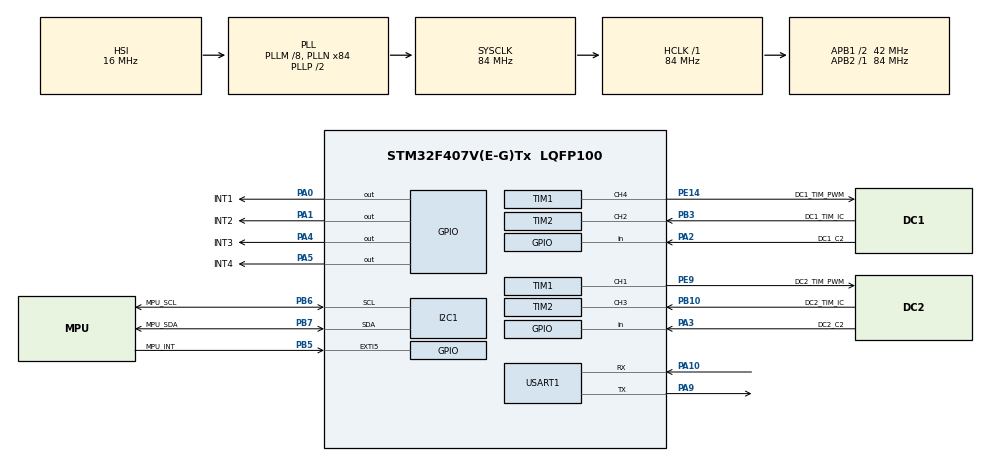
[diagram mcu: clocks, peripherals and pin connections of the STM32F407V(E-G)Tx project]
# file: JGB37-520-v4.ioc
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I2C1.I2C_Mode=I2C_Fast
Mcu.Family=STM32F4
Mcu.Name=STM32F407V(E-G)Tx
Mcu.Package=LQFP100
NVIC.EXTI9_5_IRQn=true\:0\:0\:false\:false\:true\:true\:true
NVIC.PriorityGroup=NVIC_PRIORITYGROUP_4
NVIC.TIM2_IRQn=true\:0\:0\:false\:false\:true\:true\:true
NVIC.TIM3_IRQn=true\:0\:0\:false\:false\:true\:true\:true
NVIC.TIM4_IRQn=true\:0\:0\:false\:false\:true\:true\:true
NVIC.USART1_IRQn=true\:0\:0\:false\:false\:true\:true\:true
PA0-WKUP.GPIO_Label=INT1
PA0-WKUP.GPIO_Speed=GPIO_SPEED_FREQ_HIGH
PA0-WKUP.PinState=GPIO_PIN_SET
PA0-WKUP.Signal=GPIO_Output
PA1.GPIO_Label=INT2
PA1.GPIO_Speed=GPIO_SPEED_FREQ_HIGH
PA1.PinState=GPIO_PIN_SET
PA1.Signal=GPIO_Output
PA10.Mode=Asynchronous
PA10.Signal=USART1_RX
PA13.Mode=Serial_Wire
PA13.Signal=SYS_JTMS-SWDIO
PA14.Mode=Serial_Wire
PA14.Signal=SYS_JTCK-SWCLK
PA2.GPIO_Label=DC1_C2
PA2.Signal=GPIO_Input
PA3.GPIO_Label=DC2_C2
PA3.Signal=GPIO_Input
PA4.GPIO_Label=INT3
PA4.GPIO_Speed=GPIO_SPEED_FREQ_HIGH
PA4.Signal=GPIO_Output
PA5.GPIO_Label=INT4
PA5.GPIO_Speed=GPIO_SPEED_FREQ_HIGH
PA5.Signal=GPIO_Output
PA9.Mode=Asynchronous
PA9.Signal=USART1_TX
PB10.GPIO_Label=DC2_TIM_IC
PB10.GPIO_Speed=GPIO_SPEED_FREQ_HIGH
PB10.Signal=S_TIM2_CH3
PB3.GPIO_Label=DC1_TIM_IC
PB3.GPIO_Speed=GPIO_SPEED_FREQ_HIGH
PB3.Signal=S_TIM2_CH2
PB5.GPIO_Label=MPU_INT
PB5.Signal=GPXTI5
PB6.GPIO_Label=MPU_SCL
PB6.GPIO_Speed=GPIO_SPEED_FREQ_HIGH
PB6.Mode=I2C
PB6.Signal=I2C1_SCL
PB7.GPIO_Label=MPU_SDA
PB7.GPIO_Speed=GPIO_SPEED_FREQ_HIGH
PB7.Mode=I2C
PB7.Signal=I2C1_SDA
PE14.GPIO_Label=DC1_TIM_PWM
PE14.GPIO_Speed=GPIO_SPEED_FREQ_HIGH
PE14.Signal=S_TIM1_CH4
PE9.GPIO_Label=DC2_TIM_PWM
PE9.GPIO_Speed=GPIO_SPEED_FREQ_HIGH
PE9.Signal=S_TIM1_CH1
ProjectManager.HeapSize=0x200
ProjectManager.StackSize=0x400
ProjectManager.TargetToolchain=STM32CubeIDE
RCC.48MHZClocksFreq_Value=42000000
RCC.AHBFreq_Value=84000000
RCC.APB1CLKDivider=RCC_HCLK_DIV2
RCC.APB1Freq_Value=42000000
RCC.APB1TimFreq_Value=84000000
RCC.APB2Freq_Value=84000000
RCC.APB2TimFreq_Value=84000000
RCC.CortexFreq_Value=84000000
RCC.HCLKFreq_Value=84000000
RCC.HSE_VALUE=25000000
RCC.HSI_VALUE=16000000
RCC.LSE_VALUE=32768
RCC.PLLM=8
RCC.PLLN=84
RCC.SYSCLKFreq_VALUE=84000000
RCC.SYSCLKSource=RCC_SYSCLKSOURCE_PLLCLK
RCC.VCOOutputFreq_Value=168000000
SH.S_TIM1_CH1.0=TIM1_CH1,PWM Generation1 CH1
SH.S_TIM1_CH4.0=TIM1_CH4,PWM Generation4 CH4
SH.S_TIM2_CH2.0=TIM2_CH2,Input_Capture2_from_TI2
SH.S_TIM2_CH3.0=TIM2_CH3,Input_Capture3_from_TI3
TIM1.Channel-PWM\ Generation1\ CH1=TIM_CHANNEL_1
TIM1.Channel-PWM\ Generation4\ CH4=TIM_CHANNEL_4
TIM2.Channel-Input_Capture2_from_TI2=TIM_CHANNEL_2
TIM2.Channel-Input_Capture3_from_TI3=TIM_CHANNEL_3
TIM3.Period=9999
TIM3.Prescaler=419
TIM4.Period=19999
TIM4.Prescaler=8399
USART1.VirtualMode=VM_ASYNC
VP_TIM1_VS_ClockSourceINT.Mode=Internal
VP_TIM2_VS_ClockSourceINT.Mode=Internal
VP_TIM3_VS_ClockSourceINT.Mode=Internal
VP_TIM4_VS_ClockSourceINT.Mode=Internal
board=custom

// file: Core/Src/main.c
/* USER CODE BEGIN Header */
/**
  ******************************************************************************
  * @file           : main.c
  * @brief          : Main program body
  ******************************************************************************
  * @attention
  *
  * <h2><center>&copy; Copyright (c) 2022 STMicroelectronics.
  * All rights reserved.</center></h2>
  *
  * This software component is licensed by ST under BSD 3-Clause license,
  * the "License"; You may not use this file except in compliance with the
  * License. You may obtain a copy of the License at:
  *                        opensource.org/licenses/BSD-3-Clause
  *
  ******************************************************************************
  */
/* USER CODE END Header */
#include "main.h"

I2C_HandleTypeDef hi2c1;

TIM_HandleTypeDef htim1;
TIM_HandleTypeDef htim2;
TIM_HandleTypeDef htim3;
TIM_HandleTypeDef htim4;

UART_HandleTypeDef huart1;

void SystemClock_Config(void);
static void MX_GPIO_Init(void);
static void MX_TIM1_Init(void);
static void MX_TIM2_Init(void);
static void MX_TIM3_Init(void);
static void MX_TIM4_Init(void);
static void MX_I2C1_Init(void);
static void MX_USART1_UART_Init(void);

int main(void)
{

  /* MCU Configuration--------------------------------------------------------*/

  /* Reset of all peripherals, Initializes the Flash interface and the Systick. */
  HAL_Init();

  /* Configure the system clock */
  SystemClock_Config();

  /* Initialize all configured peripherals */
  MX_GPIO_Init();
  MX_TIM1_Init();
  MX_TIM2_Init();
  MX_TIM3_Init();
  MX_TIM4_Init();
  MX_I2C1_Init();
  MX_USART1_UART_Init();
  /* USER CODE BEGIN 2 */
  HAL_GPIO_WritePin(GPIOA, GPIO_PIN_0, RESET);
  HAL_GPIO_WritePin(GPIOA, GPIO_PIN_1, SET);
//  HAL_GPIO_WritePin(GPIOA, GPIO_PIN_2, SET);

  HAL_TIM_PWM_Start(&htim1, TIM_CHANNEL_4);

  __HAL_TIM_SET_COMPARE(&htim1, TIM_CHANNEL_4, 8000);
  /* USER CODE END 2 */

  /* Infinite loop */
  while (1)
  {

  }
}

void SystemClock_Config(void)
{
  RCC_OscInitTypeDef RCC_OscInitStruct = {0};
  RCC_ClkInitTypeDef RCC_ClkInitStruct = {0};

  /** Configure the main internal regulator output voltage
  */
  __HAL_RCC_PWR_CLK_ENABLE();
  __HAL_PWR_VOLTAGESCALING_CONFIG(PWR_REGULATOR_VOLTAGE_SCALE1);
  /** Initializes the RCC Oscillators according to the specified parameters
  * in the RCC_OscInitTypeDef structure.
  */
  RCC_OscInitStruct.OscillatorType = RCC_OSCILLATORTYPE_HSI;
  RCC_OscInitStruct.HSIState = RCC_HSI_ON;
  RCC_OscInitStruct.HSICalibrationValue = RCC_HSICALIBRATION_DEFAULT;
  RCC_OscInitStruct.PLL.PLLState = RCC_PLL_ON;
  RCC_OscInitStruct.PLL.PLLSource = RCC_PLLSOURCE_HSI;
  RCC_OscInitStruct.PLL.PLLM = 8;
  RCC_OscInitStruct.PLL.PLLN = 84;
  RCC_OscInitStruct.PLL.PLLP = RCC_PLLP_DIV2;
  RCC_OscInitStruct.PLL.PLLQ = 4;
  if (HAL_RCC_OscConfig(&RCC_OscInitStruct) != HAL_OK)
  {
    Error_Handler();
  }
  /** Initializes the CPU, AHB and APB buses clocks
  */
  RCC_ClkInitStruct.ClockType = RCC_CLOCKTYPE_HCLK|RCC_CLOCKTYPE_SYSCLK
                              |RCC_CLOCKTYPE_PCLK1|RCC_CLOCKTYPE_PCLK2;
  RCC_ClkInitStruct.SYSCLKSource = RCC_SYSCLKSOURCE_PLLCLK;
  RCC_ClkInitStruct.AHBCLKDivider = RCC_SYSCLK_DIV1;
  RCC_ClkInitStruct.APB1CLKDivider = RCC_HCLK_DIV2;
  RCC_ClkInitStruct.APB2CLKDivider = RCC_HCLK_DIV1;

  if (HAL_RCC_ClockConfig(&RCC_ClkInitStruct, FLASH_LATENCY_2) != HAL_OK)
  {
    Error_Handler();
  }
}

static void MX_I2C1_Init(void)
{

  hi2c1.Instance = I2C1;
  hi2c1.Init.ClockSpeed = 400000;
  hi2c1.Init.DutyCycle = I2C_DUTYCYCLE_2;
  hi2c1.Init.OwnAddress1 = 0;
  hi2c1.Init.AddressingMode = I2C_ADDRESSINGMODE_7BIT;
  hi2c1.Init.DualAddressMode = I2C_DUALADDRESS_DISABLE;
  hi2c1.Init.OwnAddress2 = 0;
  hi2c1.Init.GeneralCallMode = I2C_GENERALCALL_DISABLE;
  hi2c1.Init.NoStretchMode = I2C_NOSTRETCH_DISABLE;
  if (HAL_I2C_Init(&hi2c1) != HAL_OK)
  {
    Error_Handler();
  }

}

static void MX_TIM1_Init(void)
{

  TIM_ClockConfigTypeDef sClockSourceConfig = {0};
  TIM_MasterConfigTypeDef sMasterConfig = {0};
  TIM_OC_InitTypeDef sConfigOC = {0};
  TIM_BreakDeadTimeConfigTypeDef sBreakDeadTimeConfig = {0};

  htim1.Instance = TIM1;
  htim1.Init.Prescaler = 0;
  htim1.Init.CounterMode = TIM_COUNTERMODE_UP;
  htim1.Init.Period = 65535;
  htim1.Init.ClockDivision = TIM_CLOCKDIVISION_DIV1;
  htim1.Init.RepetitionCounter = 0;
  htim1.Init.AutoReloadPreload = TIM_AUTORELOAD_PRELOAD_DISABLE;
  if (HAL_TIM_Base_Init(&htim1) != HAL_OK)
  {
    Error_Handler();
  }
  sClockSourceConfig.ClockSource = TIM_CLOCKSOURCE_INTERNAL;
  if (HAL_TIM_ConfigClockSource(&htim1, &sClockSourceConfig) != HAL_OK)
  {
    Error_Handler();
  }
  if (HAL_TIM_PWM_Init(&htim1) != HAL_OK)
  {
    Error_Handler();
  }
  sMasterConfig.MasterOutputTrigger = TIM_TRGO_RESET;
  sMasterConfig.MasterSlaveMode = TIM_MASTERSLAVEMODE_DISABLE;
  if (HAL_TIMEx_MasterConfigSynchronization(&htim1, &sMasterConfig) != HAL_OK)
  {
    Error_Handler();
  }
  sConfigOC.OCMode = TIM_OCMODE_PWM1;
  sConfigOC.Pulse = 0;
  sConfigOC.OCPolarity = TIM_OCPOLARITY_HIGH;
  sConfigOC.OCNPolarity = TIM_OCNPOLARITY_HIGH;
  sConfigOC.OCFastMode = TIM_OCFAST_DISABLE;
  sConfigOC.OCIdleState = TIM_OCIDLESTATE_RESET;
  sConfigOC.OCNIdleState = TIM_OCNIDLESTATE_RESET;
  if (HAL_TIM_PWM_ConfigChannel(&htim1, &sConfigOC, TIM_CHANNEL_1) != HAL_OK)
  {
    Error_Handler();
  }
  if (HAL_TIM_PWM_ConfigChannel(&htim1, &sConfigOC, TIM_CHANNEL_4) != HAL_OK)
  {
    Error_Handler();
  }
  sBreakDeadTimeConfig.OffStateRunMode = TIM_OSSR_DISABLE;
  sBreakDeadTimeConfig.OffStateIDLEMode = TIM_OSSI_DISABLE;
  sBreakDeadTimeConfig.LockLevel = TIM_LOCKLEVEL_OFF;
  sBreakDeadTimeConfig.DeadTime = 0;
  sBreakDeadTimeConfig.BreakState = TIM_BREAK_DISABLE;
  sBreakDeadTimeConfig.BreakPolarity = TIM_BREAKPOLARITY_HIGH;
  sBreakDeadTimeConfig.AutomaticOutput = TIM_AUTOMATICOUTPUT_DISABLE;
  if (HAL_TIMEx_ConfigBreakDeadTime(&htim1, &sBreakDeadTimeConfig) != HAL_OK)
  {
    Error_Handler();
  }
  HAL_TIM_MspPostInit(&htim1);

}

static void MX_TIM2_Init(void)
{

  TIM_ClockConfigTypeDef sClockSourceConfig = {0};
  TIM_MasterConfigTypeDef sMasterConfig = {0};
  TIM_IC_InitTypeDef sConfigIC = {0};

  htim2.Instance = TIM2;
  htim2.Init.Prescaler = 0;
  htim2.Init.CounterMode = TIM_COUNTERMODE_UP;
  htim2.Init.Period = 4294967295;
  htim2.Init.ClockDivision = TIM_CLOCKDIVISION_DIV1;
  htim2.Init.AutoReloadPreload = TIM_AUTORELOAD_PRELOAD_DISABLE;
  if (HAL_TIM_Base_Init(&htim2) != HAL_OK)
  {
    Error_Handler();
  }
  sClockSourceConfig.ClockSource = TIM_CLOCKSOURCE_INTERNAL;
  if (HAL_TIM_ConfigClockSource(&htim2, &sClockSourceConfig) != HAL_OK)
  {
    Error_Handler();
  }
  if (HAL_TIM_IC_Init(&htim2) != HAL_OK)
  {
    Error_Handler();
  }
  sMasterConfig.MasterOutputTrigger = TIM_TRGO_RESET;
  sMasterConfig.MasterSlaveMode = TIM_MASTERSLAVEMODE_DISABLE;
  if (HAL_TIMEx_MasterConfigSynchronization(&htim2, &sMasterConfig) != HAL_OK)
  {
    Error_Handler();
  }
  sConfigIC.ICPolarity = TIM_INPUTCHANNELPOLARITY_RISING;
  sConfigIC.ICSelection = TIM_ICSELECTION_DIRECTTI;
  sConfigIC.ICPrescaler = TIM_ICPSC_DIV1;
  sConfigIC.ICFilter = 0;
  if (HAL_TIM_IC_ConfigChannel(&htim2, &sConfigIC, TIM_CHANNEL_2) != HAL_OK)
  {
    Error_Handler();
  }
  if (HAL_TIM_IC_ConfigChannel(&htim2, &sConfigIC, TIM_CHANNEL_3) != HAL_OK)
  {
    Error_Handler();
  }

}

static void MX_TIM3_Init(void)
{

  TIM_ClockConfigTypeDef sClockSourceConfig = {0};
  TIM_MasterConfigTypeDef sMasterConfig = {0};

  htim3.Instance = TIM3;
  htim3.Init.Prescaler = 419;
  htim3.Init.CounterMode = TIM_COUNTERMODE_UP;
  htim3.Init.Period = 9999;
  htim3.Init.ClockDivision = TIM_CLOCKDIVISION_DIV1;
  htim3.Init.AutoReloadPreload = TIM_AUTORELOAD_PRELOAD_DISABLE;
  if (HAL_TIM_Base_Init(&htim3) != HAL_OK)
  {
    Error_Handler();
  }
  sClockSourceConfig.ClockSource = TIM_CLOCKSOURCE_INTERNAL;
  if (HAL_TIM_ConfigClockSource(&htim3, &sClockSourceConfig) != HAL_OK)
  {
    Error_Handler();
  }
  sMasterConfig.MasterOutputTrigger = TIM_TRGO_RESET;
  sMasterConfig.MasterSlaveMode = TIM_MASTERSLAVEMODE_DISABLE;
  if (HAL_TIMEx_MasterConfigSynchronization(&htim3, &sMasterConfig) != HAL_OK)
  {
    Error_Handler();
  }

}

static void MX_TIM4_Init(void)
{

  TIM_ClockConfigTypeDef sClockSourceConfig = {0};
  TIM_MasterConfigTypeDef sMasterConfig = {0};

  htim4.Instance = TIM4;
  htim4.Init.Prescaler = 8399;
  htim4.Init.CounterMode = TIM_COUNTERMODE_UP;
  htim4.Init.Period = 19999;
  htim4.Init.ClockDivision = TIM_CLOCKDIVISION_DIV1;
  htim4.Init.AutoReloadPreload = TIM_AUTORELOAD_PRELOAD_DISABLE;
  if (HAL_TIM_Base_Init(&htim4) != HAL_OK)
  {
    Error_Handler();
  }
  sClockSourceConfig.ClockSource = TIM_CLOCKSOURCE_INTERNAL;
  if (HAL_TIM_ConfigClockSource(&htim4, &sClockSourceConfig) != HAL_OK)
  {
    Error_Handler();
  }
  sMasterConfig.MasterOutputTrigger = TIM_TRGO_RESET;
  sMasterConfig.MasterSlaveMode = TIM_MASTERSLAVEMODE_DISABLE;
  if (HAL_TIMEx_MasterConfigSynchronization(&htim4, &sMasterConfig) != HAL_OK)
  {
    Error_Handler();
  }

}

static void MX_USART1_UART_Init(void)
{

  huart1.Instance = USART1;
  huart1.Init.BaudRate = 115200;
  huart1.Init.WordLength = UART_WORDLENGTH_8B;
  huart1.Init.StopBits = UART_STOPBITS_1;
  huart1.Init.Parity = UART_PARITY_NONE;
  huart1.Init.Mode = UART_MODE_TX_RX;
  huart1.Init.HwFlowCtl = UART_HWCONTROL_NONE;
  huart1.Init.OverSampling = UART_OVERSAMPLING_16;
  if (HAL_UART_Init(&huart1) != HAL_OK)
  {
    Error_Handler();
  }

}

static void MX_GPIO_Init(void)
{
  GPIO_InitTypeDef GPIO_InitStruct = {0};

  /* GPIO Ports Clock Enable */
  __HAL_RCC_GPIOA_CLK_ENABLE();
  __HAL_RCC_GPIOE_CLK_ENABLE();
  __HAL_RCC_GPIOB_CLK_ENABLE();

  /*Configure GPIO pin Output Level */
  HAL_GPIO_WritePin(GPIOA, INT1_Pin|INT2_Pin, GPIO_PIN_SET);

  /*Configure GPIO pin Output Level */
  HAL_GPIO_WritePin(GPIOA, INT3_Pin|INT4_Pin, GPIO_PIN_RESET);

  /*Configure GPIO pins : INT1_Pin INT2_Pin INT3_Pin INT4_Pin */
  GPIO_InitStruct.Pin = INT1_Pin|INT2_Pin|INT3_Pin|INT4_Pin;
  GPIO_InitStruct.Mode = GPIO_MODE_OUTPUT_PP;
  GPIO_InitStruct.Pull = GPIO_NOPULL;
  GPIO_InitStruct.Speed = GPIO_SPEED_FREQ_HIGH;
  HAL_GPIO_Init(GPIOA, &GPIO_InitStruct);

  /*Configure GPIO pins : DC1_C2_Pin DC2_C2_Pin */
  GPIO_InitStruct.Pin = DC1_C2_Pin|DC2_C2_Pin;
  GPIO_InitStruct.Mode = GPIO_MODE_INPUT;
  GPIO_InitStruct.Pull = GPIO_NOPULL;
  HAL_GPIO_Init(GPIOA, &GPIO_InitStruct);

  /*Configure GPIO pin : MPU_INT_Pin */
  GPIO_InitStruct.Pin = MPU_INT_Pin;
  GPIO_InitStruct.Mode = GPIO_MODE_IT_RISING;
  GPIO_InitStruct.Pull = GPIO_NOPULL;
  HAL_GPIO_Init(MPU_INT_GPIO_Port, &GPIO_InitStruct);

  /* EXTI interrupt init*/
  HAL_NVIC_SetPriority(EXTI9_5_IRQn, 0, 0);
  HAL_NVIC_EnableIRQ(EXTI9_5_IRQn);

}

void Error_Handler(void)
{
  __disable_irq();
  while (1)
  {
  }
}

/************************ (C) COPYRIGHT STMicroelectronics *****END OF FILE****/
